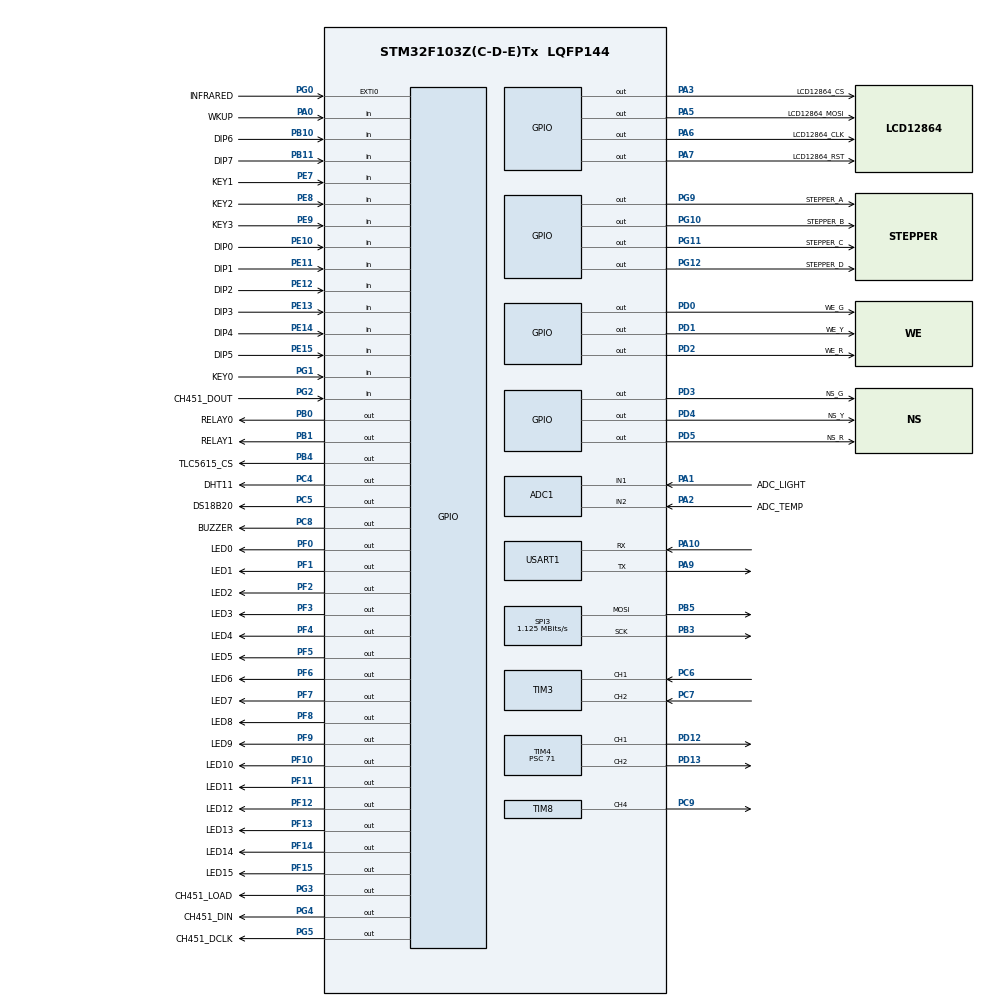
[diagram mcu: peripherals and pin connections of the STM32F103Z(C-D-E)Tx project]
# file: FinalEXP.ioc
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ADC1.Channel-0\#ChannelRegularConversion=ADC_CHANNEL_1
ADC1.Channel-1\#ChannelRegularConversion=ADC_CHANNEL_2
ADC1.ContinuousConvMode=ENABLE
ADC1.NbrOfConversion=2
ADC1.NbrOfConversionFlag=1
ADC1.Rank-0\#ChannelRegularConversion=1
ADC1.Rank-1\#ChannelRegularConversion=2
ADC1.SamplingTime-0\#ChannelRegularConversion=ADC_SAMPLETIME_71CYCLES_5
ADC1.SamplingTime-1\#ChannelRegularConversion=ADC_SAMPLETIME_71CYCLES_5
ADC1.master=1
Dma.ADC1.0.Direction=DMA_PERIPH_TO_MEMORY
Dma.ADC1.0.Instance=DMA1_Channel1
Dma.ADC1.0.MemDataAlignment=DMA_MDATAALIGN_HALFWORD
Dma.ADC1.0.MemInc=DMA_MINC_ENABLE
Dma.ADC1.0.Mode=DMA_CIRCULAR
Dma.ADC1.0.PeriphDataAlignment=DMA_PDATAALIGN_HALFWORD
Dma.ADC1.0.PeriphInc=DMA_PINC_DISABLE
Dma.ADC1.0.Priority=DMA_PRIORITY_LOW
Dma.Request0=ADC1
Dma.Request1=SPI3_TX
Dma.Request2=USART1_RX
Dma.Request3=USART1_TX
Dma.SPI3_TX.1.Direction=DMA_MEMORY_TO_PERIPH
Dma.SPI3_TX.1.Instance=DMA2_Channel2
Dma.SPI3_TX.1.MemDataAlignment=DMA_MDATAALIGN_HALFWORD
Dma.SPI3_TX.1.MemInc=DMA_MINC_ENABLE
Dma.SPI3_TX.1.Mode=DMA_NORMAL
Dma.SPI3_TX.1.PeriphDataAlignment=DMA_PDATAALIGN_HALFWORD
Dma.SPI3_TX.1.PeriphInc=DMA_PINC_DISABLE
Dma.SPI3_TX.1.Priority=DMA_PRIORITY_LOW
Dma.USART1_RX.2.Direction=DMA_PERIPH_TO_MEMORY
Dma.USART1_RX.2.Instance=DMA1_Channel5
Dma.USART1_RX.2.MemDataAlignment=DMA_MDATAALIGN_BYTE
Dma.USART1_RX.2.MemInc=DMA_MINC_ENABLE
Dma.USART1_RX.2.Mode=DMA_NORMAL
Dma.USART1_RX.2.PeriphDataAlignment=DMA_PDATAALIGN_BYTE
Dma.USART1_RX.2.PeriphInc=DMA_PINC_DISABLE
Dma.USART1_RX.2.Priority=DMA_PRIORITY_LOW
Dma.USART1_TX.3.Direction=DMA_MEMORY_TO_PERIPH
Dma.USART1_TX.3.Instance=DMA1_Channel4
Dma.USART1_TX.3.MemDataAlignment=DMA_MDATAALIGN_BYTE
Dma.USART1_TX.3.MemInc=DMA_MINC_ENABLE
Dma.USART1_TX.3.Mode=DMA_NORMAL
Dma.USART1_TX.3.PeriphDataAlignment=DMA_PDATAALIGN_BYTE
Dma.USART1_TX.3.PeriphInc=DMA_PINC_DISABLE
Dma.USART1_TX.3.Priority=DMA_PRIORITY_LOW
FREERTOS.Queues01=DIP2LCDQueue,2,uint8_t,0,Dynamic,NULL,NULL;UARTTXQueue,8,UartMsg_t,0,Dynamic,NULL,NULL
FREERTOS.Tasks01=BtnTask,24,256,StartBtnTask,Default,NULL,Dynamic,NULL,NULL;SwitchTask,16,256,StartSwitchTask,Default,NULL,Dynamic,NULL,NULL;ADCTask,24,256,StartADCTask,Default,NULL,Dynamic,NULL,NULL;UARTTask,32,384,StartUARTTask,Default,NULL,Dynamic,NULL,NULL;TrafficTask,24,256,StartTrafficTask,Default,NULL,Dynamic,NULL,NULL;DisplayTask,24,512,StartDisplayTask,Default,NULL,Dynamic,NULL,NULL;SensorTask,40,256,StartSensorTask,Default,NULL,Dynamic,NULL,NULL;MotorTask,24,256,StartMotorTask,Default,NULL,Dynamic,NULL,NULL;InfraredTask,24,256,StartInfraredTask,Default,NULL,Dynamic,NULL,NULL;DACTask,16,128,StartDACTask,Default,NULL,Dynamic,NULL,NULL;CH451Task,24,256,StartCH451Task,Default,NULL,Dynamic,NULL,NULL
FREERTOS.configTOTAL_HEAP_SIZE=16900
Mcu.Family=STM32F1
Mcu.Name=STM32F103Z(C-D-E)Tx
Mcu.Package=LQFP144
NVIC.DMA1_Channel1_IRQn=true\:5\:0\:false\:false\:true\:true\:false\:true\:true
NVIC.DMA1_Channel4_IRQn=true\:5\:0\:false\:false\:true\:true\:false\:true\:true
NVIC.DMA1_Channel5_IRQn=true\:5\:0\:false\:false\:true\:true\:false\:true\:true
NVIC.DMA2_Channel2_IRQn=true\:5\:0\:false\:false\:true\:true\:false\:true\:true
NVIC.EXTI0_IRQn=true\:5\:0\:false\:false\:true\:true\:true\:true\:true
NVIC.PriorityGroup=NVIC_PRIORITYGROUP_4
NVIC.TIM5_IRQn=true\:5\:0\:false\:false\:true\:true\:true\:true\:true
NVIC.TIM6_IRQn=true\:15\:0\:false\:false\:true\:false\:false\:true\:true
NVIC.TimeBase=TIM6_IRQn
NVIC.TimeBaseIP=TIM6
NVIC.USART1_IRQn=true\:5\:0\:false\:false\:true\:true\:true\:true\:true
OSC_IN.Mode=HSE-External-Oscillator
OSC_IN.Signal=RCC_OSC_IN
OSC_OUT.Mode=HSE-External-Oscillator
OSC_OUT.Signal=RCC_OSC_OUT
PA0-WKUP.GPIO_Label=WKUP
PA0-WKUP.Signal=GPIO_Input
PA1.GPIO_Label=ADC_LIGHT
PA1.Signal=ADCx_IN1
PA10.Mode=Asynchronous
PA10.Signal=USART1_RX
PA13.Mode=Serial_Wire
PA13.Signal=SYS_JTMS-SWDIO
PA14.Mode=Serial_Wire
PA14.Signal=SYS_JTCK-SWCLK
PA2.GPIO_Label=ADC_TEMP
PA2.Signal=ADCx_IN2
PA3.GPIO_Label=LCD12864_CS
PA3.GPIO_Speed=GPIO_SPEED_FREQ_HIGH
PA3.PinState=GPIO_PIN_SET
PA3.Signal=GPIO_Output
PA5.GPIO_Label=LCD12864_MOSI
PA5.GPIO_Speed=GPIO_SPEED_FREQ_HIGH
PA5.Signal=GPIO_Output
PA6.GPIO_Label=LCD12864_CLK
PA6.GPIO_Speed=GPIO_SPEED_FREQ_HIGH
PA6.Signal=GPIO_Output
PA7.GPIO_Label=LCD12864_RST
PA7.GPIO_Speed=GPIO_SPEED_FREQ_HIGH
PA7.Signal=GPIO_Output
PA9.Mode=Asynchronous
PA9.Signal=USART1_TX
PB0.GPIO_Label=RELAY0
PB0.Signal=GPIO_Output
PB1.GPIO_Label=RELAY1
PB1.Signal=GPIO_Output
PB10.GPIO_Label=DIP6
PB10.Signal=GPIO_Input
PB11.GPIO_Label=DIP7
PB11.Signal=GPIO_Input
PB3.Mode=TX_Only_Simplex_Unidirect_Master
PB3.Signal=SPI3_SCK
PB4.GPIO_Label=TLC5615_CS
PB4.Signal=GPIO_Output
PB5.Mode=TX_Only_Simplex_Unidirect_Master
PB5.Signal=SPI3_MOSI
PC4.GPIO_Label=DHT11
PC4.GPIO_ModeDefaultOutputPP=GPIO_MODE_OUTPUT_OD
PC4.GPIO_PuPd=GPIO_NOPULL
PC4.GPIO_Speed=GPIO_SPEED_FREQ_HIGH
PC4.PinState=GPIO_PIN_SET
PC4.Signal=GPIO_Output
PC5.GPIO_Label=DS18B20
PC5.GPIO_ModeDefaultOutputPP=GPIO_MODE_OUTPUT_OD
PC5.GPIO_PuPd=GPIO_NOPULL
PC5.GPIO_Speed=GPIO_SPEED_FREQ_HIGH
PC5.PinState=GPIO_PIN_SET
PC5.Signal=GPIO_Output
PC6.Signal=S_TIM3_CH1
PC7.Signal=S_TIM3_CH2
PC8.GPIO_Label=BUZZER
PC8.GPIO_Speed=GPIO_SPEED_FREQ_MEDIUM
PC8.Signal=GPIO_Output
PC9.Signal=S_TIM8_CH4
PD0.GPIO_Label=WE_G
PD0.GPIO_ModeDefaultOutputPP=GPIO_MODE_OUTPUT_OD
PD0.GPIO_PuPd=GPIO_NOPULL
PD0.GPIO_Speed=GPIO_SPEED_FREQ_LOW
PD0.PinState=GPIO_PIN_SET
PD0.Signal=GPIO_Output
PD1.GPIO_Label=WE_Y
PD1.GPIO_ModeDefaultOutputPP=GPIO_MODE_OUTPUT_OD
PD1.GPIO_PuPd=GPIO_NOPULL
PD1.GPIO_Speed=GPIO_SPEED_FREQ_LOW
PD1.PinState=GPIO_PIN_SET
PD1.Signal=GPIO_Output
PD12.Signal=S_TIM4_CH1
PD13.Signal=S_TIM4_CH2
PD2.GPIO_Label=WE_R
PD2.GPIO_ModeDefaultOutputPP=GPIO_MODE_OUTPUT_OD
PD2.GPIO_PuPd=GPIO_NOPULL
PD2.GPIO_Speed=GPIO_SPEED_FREQ_LOW
PD2.PinState=GPIO_PIN_SET
PD2.Signal=GPIO_Output
PD3.GPIO_Label=NS_G
PD3.GPIO_ModeDefaultOutputPP=GPIO_MODE_OUTPUT_OD
PD3.GPIO_PuPd=GPIO_NOPULL
PD3.GPIO_Speed=GPIO_SPEED_FREQ_LOW
PD3.PinState=GPIO_PIN_SET
PD3.Signal=GPIO_Output
PD4.GPIO_Label=NS_Y
PD4.GPIO_ModeDefaultOutputPP=GPIO_MODE_OUTPUT_OD
PD4.GPIO_PuPd=GPIO_NOPULL
PD4.GPIO_Speed=GPIO_SPEED_FREQ_LOW
PD4.PinState=GPIO_PIN_SET
PD4.Signal=GPIO_Output
PD5.GPIO_Label=NS_R
PD5.GPIO_ModeDefaultOutputPP=GPIO_MODE_OUTPUT_OD
PD5.GPIO_PuPd=GPIO_NOPULL
PD5.GPIO_Speed=GPIO_SPEED_FREQ_LOW
PD5.PinState=GPIO_PIN_SET
PD5.Signal=GPIO_Output
PE10.GPIO_Label=DIP0
PE10.Signal=GPIO_Input
PE11.GPIO_Label=DIP1
PE11.Signal=GPIO_Input
PE12.GPIO_Label=DIP2
PE12.Signal=GPIO_Input
PE13.GPIO_Label=DIP3
PE13.Signal=GPIO_Input
PE14.GPIO_Label=DIP4
PE14.Signal=GPIO_Input
PE15.GPIO_Label=DIP5
PE15.Signal=GPIO_Input
PE7.GPIO_Label=KEY1
PE7.Signal=GPIO_Input
PE8.GPIO_Label=KEY2
PE8.Signal=GPIO_Input
PE9.GPIO_Label=KEY3
PE9.Signal=GPIO_Input
PF0.GPIO_Label=LED0
PF0.Signal=GPIO_Output
PF1.GPIO_Label=LED1
PF1.GPIO_ModeDefaultOutputPP=GPIO_MODE_OUTPUT_OD
PF1.GPIO_PuPd=GPIO_NOPULL
PF1.PinState=GPIO_PIN_SET
PF1.Signal=GPIO_Output
PF10.GPIO_Label=LED10
PF10.GPIO_ModeDefaultOutputPP=GPIO_MODE_OUTPUT_OD
PF10.GPIO_PuPd=GPIO_NOPULL
PF10.PinState=GPIO_PIN_SET
PF10.Signal=GPIO_Output
PF11.GPIO_Label=LED11
PF11.GPIO_ModeDefaultOutputPP=GPIO_MODE_OUTPUT_OD
PF11.GPIO_PuPd=GPIO_NOPULL
PF11.PinState=GPIO_PIN_SET
PF11.Signal=GPIO_Output
PF12.GPIO_Label=LED12
PF12.GPIO_ModeDefaultOutputPP=GPIO_MODE_OUTPUT_OD
PF12.GPIO_PuPd=GPIO_NOPULL
PF12.PinState=GPIO_PIN_SET
PF12.Signal=GPIO_Output
PF13.GPIO_Label=LED13
PF13.GPIO_ModeDefaultOutputPP=GPIO_MODE_OUTPUT_OD
PF13.GPIO_PuPd=GPIO_NOPULL
PF13.PinState=GPIO_PIN_SET
PF13.Signal=GPIO_Output
PF14.GPIO_Label=LED14
PF14.GPIO_ModeDefaultOutputPP=GPIO_MODE_OUTPUT_OD
PF14.GPIO_PuPd=GPIO_NOPULL
PF14.PinState=GPIO_PIN_SET
PF14.Signal=GPIO_Output
PF15.GPIO_Label=LED15
PF15.GPIO_ModeDefaultOutputPP=GPIO_MODE_OUTPUT_OD
PF15.GPIO_PuPd=GPIO_NOPULL
PF15.PinState=GPIO_PIN_SET
PF15.Signal=GPIO_Output
PF2.GPIO_Label=LED2
PF2.GPIO_ModeDefaultOutputPP=GPIO_MODE_OUTPUT_OD
PF2.GPIO_PuPd=GPIO_NOPULL
PF2.PinState=GPIO_PIN_SET
PF2.Signal=GPIO_Output
PF3.GPIO_Label=LED3
PF3.GPIO_ModeDefaultOutputPP=GPIO_MODE_OUTPUT_OD
PF3.GPIO_PuPd=GPIO_NOPULL
PF3.PinState=GPIO_PIN_SET
PF3.Signal=GPIO_Output
PF4.GPIO_Label=LED4
PF4.GPIO_ModeDefaultOutputPP=GPIO_MODE_OUTPUT_OD
PF4.GPIO_PuPd=GPIO_NOPULL
PF4.PinState=GPIO_PIN_SET
PF4.Signal=GPIO_Output
PF5.GPIO_Label=LED5
PF5.GPIO_ModeDefaultOutputPP=GPIO_MODE_OUTPUT_OD
PF5.GPIO_PuPd=GPIO_NOPULL
PF5.PinState=GPIO_PIN_SET
PF5.Signal=GPIO_Output
PF6.GPIO_Label=LED6
PF6.GPIO_ModeDefaultOutputPP=GPIO_MODE_OUTPUT_OD
PF6.GPIO_PuPd=GPIO_NOPULL
PF6.PinState=GPIO_PIN_SET
PF6.Signal=GPIO_Output
PF7.GPIO_Label=LED7
PF7.GPIO_ModeDefaultOutputPP=GPIO_MODE_OUTPUT_OD
PF7.GPIO_PuPd=GPIO_NOPULL
PF7.PinState=GPIO_PIN_SET
PF7.Signal=GPIO_Output
PF8.GPIO_Label=LED8
PF8.GPIO_ModeDefaultOutputPP=GPIO_MODE_OUTPUT_OD
PF8.GPIO_PuPd=GPIO_NOPULL
PF8.PinState=GPIO_PIN_SET
PF8.Signal=GPIO_Output
PF9.GPIO_Label=LED9
PF9.GPIO_ModeDefaultOutputPP=GPIO_MODE_OUTPUT_OD
PF9.GPIO_PuPd=GPIO_NOPULL
PF9.PinState=GPIO_PIN_SET
PF9.Signal=GPIO_Output
PG0.GPIO_Label=INFRARED
PG0.GPIO_ModeDefaultEXTI=GPIO_MODE_IT_RISING_FALLING
PG0.Signal=GPXTI0
PG1.GPIO_Label=KEY0
PG1.Signal=GPIO_Input
PG10.GPIO_Label=STEPPER_B
PG10.PinState=GPIO_PIN_SET
PG10.Signal=GPIO_Output
PG11.GPIO_Label=STEPPER_C
PG11.PinState=GPIO_PIN_SET
PG11.Signal=GPIO_Output
PG12.GPIO_Label=STEPPER_D
PG12.PinState=GPIO_PIN_SET
PG12.Signal=GPIO_Output
PG2.GPIO_Label=CH451_DOUT
PG2.Signal=GPIO_Input
PG3.GPIO_Label=CH451_LOAD
PG3.GPIO_ModeDefaultOutputPP=GPIO_MODE_OUTPUT_PP
PG3.GPIO_Speed=GPIO_SPEED_FREQ_HIGH
PG3.PinState=GPIO_PIN_SET
PG3.Signal=GPIO_Output
PG4.GPIO_Label=CH451_DIN
PG4.GPIO_ModeDefaultOutputPP=GPIO_MODE_OUTPUT_PP
PG4.GPIO_Speed=GPIO_SPEED_FREQ_HIGH
PG4.PinState=GPIO_PIN_SET
PG4.Signal=GPIO_Output
PG5.GPIO_Label=CH451_DCLK
PG5.GPIO_ModeDefaultOutputPP=GPIO_MODE_OUTPUT_PP
PG5.GPIO_Speed=GPIO_SPEED_FREQ_HIGH
PG5.PinState=GPIO_PIN_SET
PG5.Signal=GPIO_Output
PG9.GPIO_Label=STEPPER_A
PG9.PinState=GPIO_PIN_SET
PG9.Signal=GPIO_Output
ProjectManager.HeapSize=0x200
ProjectManager.StackSize=0x400
ProjectManager.TargetToolchain=CMake
RCC.ADCPresc=RCC_ADCPCLK2_DIV6
RCC.AHBFreq_Value=72000000
RCC.APB1CLKDivider=RCC_HCLK_DIV2
RCC.APB1Freq_Value=36000000
RCC.APB1TimFreq_Value=72000000
RCC.APB2Freq_Value=72000000
RCC.APB2TimFreq_Value=72000000
RCC.HCLKFreq_Value=72000000
RCC.PLLMUL=RCC_PLL_MUL9
RCC.PLLSourceVirtual=RCC_PLLSOURCE_HSE
RCC.SYSCLKFreq_VALUE=72000000
RCC.SYSCLKSource=RCC_SYSCLKSOURCE_PLLCLK
RCC.USBFreq_Value=72000000
SH.ADCx_IN1.0=ADC1_IN1,IN1
SH.ADCx_IN2.0=ADC1_IN2,IN2
SH.S_TIM3_CH1.0=TIM3_CH1,Encoder_Interface
SH.S_TIM3_CH2.0=TIM3_CH2,Encoder_Interface
SH.S_TIM4_CH1.0=TIM4_CH1,PWM Generation1 CH1
SH.S_TIM4_CH2.0=TIM4_CH2,PWM Generation2 CH2
SH.S_TIM8_CH4.0=TIM8_CH4,PWM Generation4 CH4
SPI3.BaudRatePrescaler=SPI_BAUDRATEPRESCALER_32
SPI3.CalculateBaudRate=1.125 MBits/s
SPI3.DataSize=SPI_DATASIZE_16BIT
SPI3.Direction=SPI_DIRECTION_2LINES
SPI3.Mode=SPI_MODE_MASTER
SPI3.VirtualType=VM_MASTER
TIM3.AutoReloadPreload=TIM_AUTORELOAD_PRELOAD_ENABLE
TIM3.EncoderMode=TIM_ENCODERMODE_TI12
TIM3.IC2Polarity=TIM_ICPOLARITY_FALLING
TIM4.AutoReloadPreload=TIM_AUTORELOAD_PRELOAD_ENABLE
TIM4.Channel-PWM\ Generation1\ CH1=TIM_CHANNEL_1
TIM4.Channel-PWM\ Generation2\ CH2=TIM_CHANNEL_2
TIM4.Period=999
TIM4.Prescaler=71
TIM5.AutoReloadPreload=TIM_AUTORELOAD_PRELOAD_ENABLE
TIM5.Period=29999
TIM5.Prescaler=7199
TIM7.AutoReloadPreload=TIM_AUTORELOAD_PRELOAD_ENABLE
TIM7.Prescaler=71
TIM8.AutoReloadPreload=TIM_AUTORELOAD_PRELOAD_ENABLE
TIM8.Channel-PWM\ Generation4\ CH4=TIM_CHANNEL_4
TIM8.Period=1999
TIM8.Prescaler=719
USART1.VirtualMode=VM_ASYNC
VP_FREERTOS_VS_CMSIS_V2.Mode=CMSIS_V2
VP_SYS_VS_tim6.Mode=TIM6
VP_TIM4_VS_ClockSourceINT.Mode=Internal
VP_TIM5_VS_ClockSourceINT.Mode=Internal
VP_TIM7_VS_ClockSourceINT.Mode=Enable_Timer
VP_TIM8_VS_ClockSourceINT.Mode=Internal
board=custom

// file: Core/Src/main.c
/* USER CODE BEGIN Header */
/**
 ******************************************************************************
 * @file           : main.c
 * @brief          : Main program body
 ******************************************************************************
 * @attention
 *
 * Copyright (c) 2026 STMicroelectronics.
 * All rights reserved.
 *
 * This software is licensed under terms that can be found in the LICENSE file
 * in the root directory of this software component.
 * If no LICENSE file comes with this software, it is provided AS-IS.
 *
 ******************************************************************************
 */
/* USER CODE END Header */
#include "main.h"
#include "adc.h"
#include "cmsis_os.h"
#include "dma.h"
#include "gpio.h"
#include "spi.h"
#include "tim.h"
#include "usart.h"

/* USER CODE BEGIN Includes */
#include "DelayUs.h"
#include "KeyScan.h"
#include "LCD12864.h"
#include "btn.h"
#include "dc_motor.h"
#include "ir_receiver.h"
#include <string.h>

/* USER CODE END Includes */

/* USER CODE BEGIN PV */
volatile uint16_t
  adc_value[2]; // 存放 ADC 值，adc_value[0] 存放光敏电阻的采样值，adc_value[1] 存放热敏电阻的采样值
uint8_t rxData[50]; // 接收缓冲区（用于回显）

/* USER CODE END PV */

void SystemClock_Config(void);
void MX_FREERTOS_Init(void);
/* USER CODE BEGIN PFP */
extern osMessageQueueId_t UARTTXQueueHandle;

/* USER CODE END PFP */

/* USER CODE BEGIN 0 */
LED_DisplayMode_t LED_displayMode = LED_DISPLAY_LIGHT;          // 默认显示光敏电阻的采样值
TrafficLightState_t trafficLightState = NS_GREEN_WE_RED;        // 初始化交通灯状态为南北绿，东西红
volatile DeviceControlMode_t deviceControlMode = RELAY_CONTROL; // 初始化设备控制模式为继电器控制
volatile MotorStartStopState_t motorStartStopState = MOTOR_OFF; // 初始化电机开关状态为关闭
volatile MotorMode_t motorMode = MOTOR_MODE1;                   // 初始化电机预设模式
/* USER CODE END 0 */

int
main(void)
{

    /* MCU Configuration--------------------------------------------------------*/

    /* Reset of all peripherals, Initializes the Flash interface and the Systick. */

    HAL_Init();

    /* Configure the system clock */
    SystemClock_Config();

    /* Initialize all configured peripherals */
    MX_GPIO_Init();
    MX_DMA_Init();
    MX_ADC1_Init();
    MX_USART1_UART_Init();
    MX_TIM5_Init();
    MX_SPI3_Init();
    MX_TIM8_Init();
    MX_TIM4_Init();
    MX_TIM7_Init();
    MX_TIM3_Init();
    /* USER CODE BEGIN 2 */
    // 初始化按键
    Btn_Init();
    KeyScan_Init();

    Delay_Init();

    // 初始化 LCD12864
    LCD_Init();
    LCD_Clear();
    IR_Receiver_Init(); // 初始化红外接收器

    // 启动 ADC DMA 采集，连续采集光敏电阻和热敏电阻的模拟值，并存放到 adc_value 数组中
    HAL_ADC_Start_DMA(&hadc1, (uint32_t *)adc_value, 2);

    // 启动 TIM5 中断，用于每 3 秒切换一次交通灯状态
    HAL_TIM_Base_Start_IT(&htim5);

    // 启动 UART 接收，使用空闲中断模式，接收数据存放到 rxData 数组中
    HAL_UARTEx_ReceiveToIdle_DMA(&huart1, rxData, sizeof(rxData));

    // 关闭 DMA 传输过半中断
    __HAL_DMA_DISABLE_IT(&hdma_usart1_rx, DMA_IT_HT);
    /* USER CODE END 2 */

    /* Init scheduler */
    osKernelInitialize(); /* Call init function for freertos objects (in cmsis_os2.c) */
    MX_FREERTOS_Init();

    /* Start scheduler */
    osKernelStart();

    /* We should never get here as control is now taken by the scheduler */

    /* Infinite loop */
    while(1)
    {

    }
}

void
SystemClock_Config(void)
{
    RCC_OscInitTypeDef RCC_OscInitStruct = { 0 };
    RCC_ClkInitTypeDef RCC_ClkInitStruct = { 0 };
    RCC_PeriphCLKInitTypeDef PeriphClkInit = { 0 };

    /** Initializes the RCC Oscillators according to the specified parameters
     * in the RCC_OscInitTypeDef structure.
     */
    RCC_OscInitStruct.OscillatorType = RCC_OSCILLATORTYPE_HSE;
    RCC_OscInitStruct.HSEState = RCC_HSE_ON;
    RCC_OscInitStruct.HSEPredivValue = RCC_HSE_PREDIV_DIV1;
    RCC_OscInitStruct.HSIState = RCC_HSI_ON;
    RCC_OscInitStruct.PLL.PLLState = RCC_PLL_ON;
    RCC_OscInitStruct.PLL.PLLSource = RCC_PLLSOURCE_HSE;
    RCC_OscInitStruct.PLL.PLLMUL = RCC_PLL_MUL9;
    if(HAL_RCC_OscConfig(&RCC_OscInitStruct) != HAL_OK)
    {
        Error_Handler();
    }

    /** Initializes the CPU, AHB and APB buses clocks
     */
    RCC_ClkInitStruct.ClockType =
      RCC_CLOCKTYPE_HCLK | RCC_CLOCKTYPE_SYSCLK | RCC_CLOCKTYPE_PCLK1 | RCC_CLOCKTYPE_PCLK2;
    RCC_ClkInitStruct.SYSCLKSource = RCC_SYSCLKSOURCE_PLLCLK;
    RCC_ClkInitStruct.AHBCLKDivider = RCC_SYSCLK_DIV1;
    RCC_ClkInitStruct.APB1CLKDivider = RCC_HCLK_DIV2;
    RCC_ClkInitStruct.APB2CLKDivider = RCC_HCLK_DIV1;

    if(HAL_RCC_ClockConfig(&RCC_ClkInitStruct, FLASH_LATENCY_2) != HAL_OK)
    {
        Error_Handler();
    }
    PeriphClkInit.PeriphClockSelection = RCC_PERIPHCLK_ADC;
    PeriphClkInit.AdcClockSelection = RCC_ADCPCLK2_DIV6;
    if(HAL_RCCEx_PeriphCLKConfig(&PeriphClkInit) != HAL_OK)
    {
        Error_Handler();
    }
}

/* USER CODE BEGIN 4 */
void
HAL_UARTEx_RxEventCallback(UART_HandleTypeDef *huart, uint16_t Size)
{
    if(huart->Instance == USART1)
    {
        // 回显接收到的数据（通过 UART 发送队列）
        if(UARTTXQueueHandle != NULL)
        {
            UartMsg_t msg;
            uint16_t copy_len = Size;

            if(copy_len > UART_TX_MAX_LEN)
            {
                copy_len = UART_TX_MAX_LEN;
            }

            msg.len = copy_len;
            memcpy(msg.data, rxData, copy_len);
            (void)osMessageQueuePut(UARTTXQueueHandle, &msg, 0, 0);
        }
        // 重新启动 UART 接收
        HAL_UARTEx_ReceiveToIdle_DMA(&huart1, rxData, sizeof(rxData));
    }
}
/* USER CODE END 4 */

void
HAL_TIM_PeriodElapsedCallback(TIM_HandleTypeDef *htim)
{
    /* USER CODE BEGIN Callback 0 */
    if(htim->Instance == TIM5)
    {
        // 每 3 秒切换一次交通灯状态
        switch(trafficLightState)
        {
            case NS_GREEN_WE_RED:
                trafficLightState = NS_YELLOW_WE_RED;
                break;

            case NS_YELLOW_WE_RED:
                trafficLightState = NS_RED_WE_GREEN;
                break;

            case NS_RED_WE_GREEN:
                trafficLightState = NS_RED_WE_YELLOW;
                break;

            case NS_RED_WE_YELLOW:
                trafficLightState = NS_GREEN_WE_RED;
                break;
        }
    }
    /* USER CODE END Callback 0 */
    if(htim->Instance == TIM6)
    {
        HAL_IncTick();
    }
}

void
Error_Handler(void)
{
    __disable_irq();
    while(1)
    {
    }
}

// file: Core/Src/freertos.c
/* USER CODE BEGIN Header */
/**
 ******************************************************************************
 * File Name          : freertos.c
 * Description        : Code for freertos applications
 ******************************************************************************
 * @attention
 *
 * Copyright (c) 2026 STMicroelectronics.
 * All rights reserved.
 *
 * This software is licensed under terms that can be found in the LICENSE file
 * in the root directory of this software component.
 * If no LICENSE file comes with this software, it is provided AS-IS.
 *
 ******************************************************************************
 */
/* USER CODE END Header */

#include "FreeRTOS.h"
#include "cmsis_os.h"
#include "main.h"
#include "task.h"

/* USER CODE BEGIN Includes */
#include "KeyScan.h"
#include "LCD12864.h"
#include "btn.h"
#include "ch451.h"
#include "dc_motor.h"
#include "dht11.h"
#include "ds18b20.h"
#include "ir_receiver.h"
#include "led.h"
#include "servo_motor.h"
#include "spi.h"
#include "stepper_motor.h"
#include "usart.h"
#include <stdio.h>
#include <string.h>

/* USER CODE END Includes */

/* USER CODE BEGIN PD */
#define BTN_DEBOUNCE_DELAY 40 // 按键消抖时间，单位 ms
/* USER CODE END PD */

/* Definitions for BtnTask */
osThreadId_t BtnTaskHandle;
const osThreadAttr_t BtnTask_attributes = {
    .name = "BtnTask",
    .stack_size = 256 * 4,
    .priority = (osPriority_t)osPriorityNormal,
};
/* Definitions for SwitchTask */
osThreadId_t SwitchTaskHandle;
const osThreadAttr_t SwitchTask_attributes = {
    .name = "SwitchTask",
    .stack_size = 256 * 4,
    .priority = (osPriority_t)osPriorityBelowNormal,
};
/* Definitions for ADCTask */
osThreadId_t ADCTaskHandle;
const osThreadAttr_t ADCTask_attributes = {
    .name = "ADCTask",
    .stack_size = 256 * 4,
    .priority = (osPriority_t)osPriorityNormal,
};
/* Definitions for UARTTask */
osThreadId_t UARTTaskHandle;
const osThreadAttr_t UARTTask_attributes = {
    .name = "UARTTask",
    .stack_size = 384 * 4,
    .priority = (osPriority_t)osPriorityAboveNormal,
};
/* Definitions for TrafficTask */
osThreadId_t TrafficTaskHandle;
const osThreadAttr_t TrafficTask_attributes = {
    .name = "TrafficTask",
    .stack_size = 256 * 4,
    .priority = (osPriority_t)osPriorityNormal,
};
/* Definitions for DisplayTask */
osThreadId_t DisplayTaskHandle;
const osThreadAttr_t DisplayTask_attributes = {
    .name = "DisplayTask",
    .stack_size = 512 * 4,
    .priority = (osPriority_t)osPriorityNormal,
};
/* Definitions for SensorTask */
osThreadId_t SensorTaskHandle;
const osThreadAttr_t SensorTask_attributes = {
    .name = "SensorTask",
    .stack_size = 256 * 4,
    .priority = (osPriority_t)osPriorityHigh,
};
/* Definitions for MotorTask */
osThreadId_t MotorTaskHandle;
const osThreadAttr_t MotorTask_attributes = {
    .name = "MotorTask",
    .stack_size = 256 * 4,
    .priority = (osPriority_t)osPriorityNormal,
};
/* Definitions for InfraredTask */
osThreadId_t InfraredTaskHandle;
const osThreadAttr_t InfraredTask_attributes = {
    .name = "InfraredTask",
    .stack_size = 256 * 4,
    .priority = (osPriority_t)osPriorityNormal,
};
/* Definitions for DACTask */
osThreadId_t DACTaskHandle;
const osThreadAttr_t DACTask_attributes = {
    .name = "DACTask",
    .stack_size = 128 * 4,
    .priority = (osPriority_t)osPriorityBelowNormal,
};
/* Definitions for CH451Task */
osThreadId_t CH451TaskHandle;
const osThreadAttr_t CH451Task_attributes = {
    .name = "CH451Task",
    .stack_size = 256 * 4,
    .priority = (osPriority_t)osPriorityNormal,
};
/* Definitions for DIP2LCDQueue */
osMessageQueueId_t DIP2LCDQueueHandle;
const osMessageQueueAttr_t DIP2LCDQueue_attributes = { .name = "DIP2LCDQueue" };
/* Definitions for UARTTXQueue */
osMessageQueueId_t UARTTXQueueHandle;
const osMessageQueueAttr_t UARTTXQueue_attributes = { .name = "UARTTXQueue" };

void StartBtnTask(void *argument);
void StartSwitchTask(void *argument);
void StartADCTask(void *argument);
void StartUARTTask(void *argument);
void StartTrafficTask(void *argument);
void StartDisplayTask(void *argument);
void StartSensorTask(void *argument);
void StartMotorTask(void *argument);
void StartInfraredTask(void *argument);
void StartDACTask(void *argument);
void StartCH451Task(void *argument);

void MX_FREERTOS_Init(void); /* (MISRA C 2004 rule 8.1) */

void
MX_FREERTOS_Init(void)
{

    /* Create the queue(s) */
    /* creation of DIP2LCDQueue */
    DIP2LCDQueueHandle = osMessageQueueNew(2, sizeof(uint8_t), &DIP2LCDQueue_attributes);

    /* creation of UARTTXQueue */
    UARTTXQueueHandle = osMessageQueueNew(8, sizeof(UartMsg_t), &UARTTXQueue_attributes);

    /* Create the thread(s) */
    /* creation of BtnTask */
    BtnTaskHandle = osThreadNew(StartBtnTask, NULL, &BtnTask_attributes);

    /* creation of SwitchTask */
    SwitchTaskHandle = osThreadNew(StartSwitchTask, NULL, &SwitchTask_attributes);

    /* creation of ADCTask */
    ADCTaskHandle = osThreadNew(StartADCTask, NULL, &ADCTask_attributes);

    /* creation of UARTTask */
    UARTTaskHandle = osThreadNew(StartUARTTask, NULL, &UARTTask_attributes);

    /* creation of TrafficTask */
    TrafficTaskHandle = osThreadNew(StartTrafficTask, NULL, &TrafficTask_attributes);

    /* creation of DisplayTask */
    DisplayTaskHandle = osThreadNew(StartDisplayTask, NULL, &DisplayTask_attributes);

    /* creation of SensorTask */
    SensorTaskHandle = osThreadNew(StartSensorTask, NULL, &SensorTask_attributes);

    /* creation of MotorTask */
    MotorTaskHandle = osThreadNew(StartMotorTask, NULL, &MotorTask_attributes);

    /* creation of InfraredTask */
    InfraredTaskHandle = osThreadNew(StartInfraredTask, NULL, &InfraredTask_attributes);

    /* creation of DACTask */
    DACTaskHandle = osThreadNew(StartDACTask, NULL, &DACTask_attributes);

    /* creation of CH451Task */
    CH451TaskHandle = osThreadNew(StartCH451Task, NULL, &CH451Task_attributes);

}

void
StartBtnTask(void *argument)
{
    /* USER CODE BEGIN StartBtnTask */
    uint8_t debounceCounter; // 消抖计数器
    /* Infinite loop */
    for(;;)
    {
        // 读取按键状态
        uint8_t btnPressed = HAL_GPIO_ReadPin(WKUP_GPIO_Port, WKUP_Pin) == GPIO_PIN_RESET;
        switch(btnState)
        {
            case BTN_STATE_IDLE:
                if(btnPressed)
                {
                    btnState = BTN_STATE_DEBOUNCE;
                    debounceCounter = 0;
                }
                break;

            case BTN_STATE_DEBOUNCE:
                if(btnPressed)
                {
                    debounceCounter++;
                    if(debounceCounter >= BTN_DEBOUNCE_DELAY / 20)
                    { // 每 20 ms 检查一次
                        btnState = BTN_STATE_PRESSED;
                    }
                }
                else
                {
                    btnState = BTN_STATE_IDLE; // 按键抖动，回到空闲状态
                }
                break;

            case BTN_STATE_PRESSED:
                if(btnPressed)
                {
                    break;
                }

                btnEvent = BTN_EVENT_CLICK; // 点击事件
                btnState = BTN_STATE_IDLE;  // 回到空闲状态
                break;
        }

        KeyScan_ScanAll(); // 检测四个独立按键的状态

        osDelay(20);
    }
    /* USER CODE END StartBtnTask */
}

void
StartSwitchTask(void *argument)
{
    /* USER CODE BEGIN StartSwitchTask */
    /* Infinite loop */
    for(;;)
    {
        // 读取 DIP 开关状态，发送到 DisplayTask 显示
        uint8_t dipState = 0;
        dipState |= (HAL_GPIO_ReadPin(DIP0_GPIO_Port, DIP0_Pin) == GPIO_PIN_RESET) ? 0x01 : 0x00;
        dipState |= (HAL_GPIO_ReadPin(DIP1_GPIO_Port, DIP1_Pin) == GPIO_PIN_RESET) ? 0x02 : 0x00;
        dipState |= (HAL_GPIO_ReadPin(DIP2_GPIO_Port, DIP2_Pin) == GPIO_PIN_RESET) ? 0x04 : 0x00;
        dipState |= (HAL_GPIO_ReadPin(DIP3_GPIO_Port, DIP3_Pin) == GPIO_PIN_RESET) ? 0x08 : 0x00;
        dipState |= (HAL_GPIO_ReadPin(DIP4_GPIO_Port, DIP4_Pin) == GPIO_PIN_RESET) ? 0x10 : 0x00;
        dipState |= (HAL_GPIO_ReadPin(DIP5_GPIO_Port, DIP5_Pin) == GPIO_PIN_RESET) ? 0x20 : 0x00;
        dipState |= (HAL_GPIO_ReadPin(DIP6_GPIO_Port, DIP6_Pin) == GPIO_PIN_RESET) ? 0x40 : 0x00;
        dipState |= (HAL_GPIO_ReadPin(DIP7_GPIO_Port, DIP7_Pin) == GPIO_PIN_RESET) ? 0x80 : 0x00;
        osMessageQueuePut(DIP2LCDQueueHandle, &dipState, 0, 0);

        // 独立按键 KEY3 控制设备控制模式的切换
        if(keyEvent[3] == KEY_EVENT_CLICK)
        {
            keyEvent[3] = KEY_EVENT_NONE; // 清除事件
            switch(deviceControlMode)
            {
                case RELAY_CONTROL:
                    deviceControlMode = STEPPER_MOTOR_CONTROL;
                    break;

                case STEPPER_MOTOR_CONTROL:
                    deviceControlMode = DC_MOTOR_CONTROL;
                    break;

                case DC_MOTOR_CONTROL:
                    deviceControlMode = SERVO_MOTOR_CONTROL;
                    break;

                case SERVO_MOTOR_CONTROL:
                    deviceControlMode = RELAY_CONTROL;
                    break;
            }

            // 切换设备控制模式时，电机关闭，预设模式重置
            motorStartStopState = MOTOR_OFF;
            motorMode = MOTOR_MODE1;
        }

        // 处于继电器控制模式时，独立按键 KEY0 和 KEY1 控制继电器 RELAY0 和 RELAY1 的开关
        if(deviceControlMode == RELAY_CONTROL)
        {
            // 根据独立按键 KEY0 和 KEY1 的状态，控制继电器 RELAY0 和 RELAY1 的开关
            if(keyEvent[0] == KEY_EVENT_CLICK)
            {
                keyEvent[0] = KEY_EVENT_NONE; // 清除事件
                HAL_GPIO_TogglePin(RELAY0_GPIO_Port, RELAY0_Pin);
            }
            if(keyEvent[1] == KEY_EVENT_CLICK)
            {
                keyEvent[1] = KEY_EVENT_NONE; // 清除事件
                HAL_GPIO_TogglePin(RELAY1_GPIO_Port, RELAY1_Pin);
            }
        }
        else
        {
            // 非继电器控制模式下，继电器断开
            HAL_GPIO_WritePin(RELAY0_GPIO_Port, RELAY0_Pin, GPIO_PIN_RESET);
            HAL_GPIO_WritePin(RELAY1_GPIO_Port, RELAY1_Pin, GPIO_PIN_RESET);
        }
        osDelay(100);
    }
    /* USER CODE END StartSwitchTask */
}

void
StartADCTask(void *argument)
{
    /* USER CODE BEGIN StartADCTask */

    /* Infinite loop */
    for(;;)
    {
        // 根据按键事件切换显示模式
        if(btnEvent == BTN_EVENT_CLICK)
        {
            btnEvent = BTN_EVENT_NONE; // 清除事件
            if(LED_displayMode == LED_DISPLAY_LIGHT)
            {
                LED_displayMode = LED_DISPLAY_TEMP; // 切换到显示热敏电阻
            }
            else
            {
                LED_displayMode = LED_DISPLAY_LIGHT; // 切换到显示光敏电阻
            }
        }

        // 根据当前显示模式，切换 LED 显示光敏电阻的采样值还是热敏电阻的采样值
        if(LED_displayMode == LED_DISPLAY_LIGHT)
        {
            // 通过板载 LED 显示光敏电阻的采样值，adc_value[0]，范围 0~4095，点亮 LED0 到 LED11
            LED_Binary_Display(adc_value[0]);
        }
        else if(LED_displayMode == LED_DISPLAY_TEMP)
        {
            // 通过板载 LED 显示热敏电阻的采样值，adc_value[1]，范围 0~4095，点亮 LED0 到 LED11
            LED_Binary_Display(adc_value[1]);
        }
        osDelay(200);
    }
    /* USER CODE END StartADCTask */
}

void
StartUARTTask(void *argument)
{
    /* USER CODE BEGIN StartUARTTask */
    UartMsg_t msg;
    /* Infinite loop */
    for(;;)
    {
        // 从 UART 接收队列获取数据，并通过 UART 发送出去
        if(osMessageQueueGet(UARTTXQueueHandle, &msg, NULL, osWaitForever) == osOK)
        {
            if(msg.len > 0)
            {
                if(msg.len > UART_TX_MAX_LEN)
                {
                    msg.len = UART_TX_MAX_LEN;
                }

                while(HAL_UART_Transmit_DMA(&huart1, msg.data, msg.len) != HAL_OK)
                {
                    osDelay(10);
                }

                while(huart1.gState != HAL_UART_STATE_READY)
                {
                    osDelay(10);
                }
            }
        }
        osDelay(100);
    }
    /* USER CODE END StartUARTTask */
}

void
StartTrafficTask(void *argument)
{
    /* USER CODE BEGIN StartTrafficTask */
    /* Infinite loop */
    for(;;)
    {
        // 根据 trafficLightState 的状态，控制交通灯的 LED 显示(低电平点亮 LED)
        switch(trafficLightState)
        {
            case NS_GREEN_WE_RED:
                HAL_GPIO_WritePin(NS_G_GPIO_Port, NS_G_Pin, GPIO_PIN_RESET);
                HAL_GPIO_WritePin(NS_Y_GPIO_Port, NS_Y_Pin, GPIO_PIN_SET);
                HAL_GPIO_WritePin(NS_R_GPIO_Port, NS_R_Pin, GPIO_PIN_SET);
                HAL_GPIO_WritePin(WE_G_GPIO_Port, WE_G_Pin, GPIO_PIN_SET);
                HAL_GPIO_WritePin(WE_Y_GPIO_Port, WE_Y_Pin, GPIO_PIN_SET);
                HAL_GPIO_WritePin(WE_R_GPIO_Port, WE_R_Pin, GPIO_PIN_RESET);
                break;

            case NS_YELLOW_WE_RED:
                HAL_GPIO_WritePin(NS_G_GPIO_Port, NS_G_Pin, GPIO_PIN_SET);
                HAL_GPIO_WritePin(NS_Y_GPIO_Port, NS_Y_Pin, GPIO_PIN_RESET);
                HAL_GPIO_WritePin(NS_R_GPIO_Port, NS_R_Pin, GPIO_PIN_SET);
                HAL_GPIO_WritePin(WE_G_GPIO_Port, WE_G_Pin, GPIO_PIN_SET);
                HAL_GPIO_WritePin(WE_Y_GPIO_Port, WE_Y_Pin, GPIO_PIN_SET);
                HAL_GPIO_WritePin(WE_R_GPIO_Port, WE_R_Pin, GPIO_PIN_RESET);
                break;

            case NS_RED_WE_GREEN:
                HAL_GPIO_WritePin(NS_G_GPIO_Port, NS_G_Pin, GPIO_PIN_SET);
                HAL_GPIO_WritePin(NS_Y_GPIO_Port, NS_Y_Pin, GPIO_PIN_SET);
                HAL_GPIO_WritePin(NS_R_GPIO_Port, NS_R_Pin, GPIO_PIN_RESET);
                HAL_GPIO_WritePin(WE_G_GPIO_Port, WE_G_Pin, GPIO_PIN_RESET);
                HAL_GPIO_WritePin(WE_Y_GPIO_Port, WE_Y_Pin, GPIO_PIN_SET);
                HAL_GPIO_WritePin(WE_R_GPIO_Port, WE_R_Pin, GPIO_PIN_SET);
                break;

            case NS_RED_WE_YELLOW:
                HAL_GPIO_WritePin(NS_G_GPIO_Port, NS_G_Pin, GPIO_PIN_SET);
                HAL_GPIO_WritePin(NS_Y_GPIO_Port, NS_Y_Pin, GPIO_PIN_SET);
                HAL_GPIO_WritePin(NS_R_GPIO_Port, NS_R_Pin, GPIO_PIN_RESET);
                HAL_GPIO_WritePin(WE_G_GPIO_Port, WE_G_Pin, GPIO_PIN_SET);
                HAL_GPIO_WritePin(WE_Y_GPIO_Port, WE_Y_Pin, GPIO_PIN_RESET);
                HAL_GPIO_WritePin(WE_R_GPIO_Port, WE_R_Pin, GPIO_PIN_SET);
                break;
        }
        osDelay(1000);
    }
    /* USER CODE END StartTrafficTask */
}

void
StartDisplayTask(void *argument)
{
    /* USER CODE BEGIN StartDisplayTask */
    // 显存
    char row1[17] = { 0 };
    char row2[17] = { 0 };
    char row3[17] = { 0 };
    char row4[17] = { 0 };
    char row1Text[32] = { 0 };
    char row4Text[32] = { 0 };

    const char *trafficText = "NS:Green WE:Red  ";
    const char *deviceControlText[] = { "Relay Ctrl", "Stepper   ", "DC Motor  ", "Servo     " };
    /* Infinite loop */
    for(;;)
    {
        // 在 LCD 上显示当前的设备控制模式；非继电器模式时追加开关状态
        if(deviceControlMode == RELAY_CONTROL)
        {
            snprintf(row1Text, sizeof(row1Text), "%s", deviceControlText[deviceControlMode]);
        }
        else
        {
            if(motorStartStopState == MOTOR_ON)
            {
                snprintf(row1Text,
                         sizeof(row1Text),
                         "%s %u ON ",
                         deviceControlText[deviceControlMode],
                         (unsigned int)motorMode + 1U);
            }
            else
            {
                snprintf(row1Text,
                         sizeof(row1Text),
                         "%s %u OFF",
                         deviceControlText[deviceControlMode],
                         (unsigned int)motorMode + 1U);
            }
        }
        memset(row1, ' ', 16);
        memcpy(row1, row1Text, strlen(row1Text) > 16 ? 16 : strlen(row1Text));
        row1[16] = '\0';
        LCD_DispString(ROW1, COL1, row1);

        // 在 LCD 上显示当前的交通灯状态，显示在第二行
        switch(trafficLightState)
        {
            case NS_GREEN_WE_RED:
                trafficText = "NS:Green WE:Red  ";
                break;

            case NS_YELLOW_WE_RED:
                trafficText = "NS:Yellow WE:Red ";
                break;

            case NS_RED_WE_GREEN:
                trafficText = "NS:Red WE:Green  ";
                break;

            case NS_RED_WE_YELLOW:
                trafficText = "NS:Red WE:Yellow ";
                break;
        }

        memcpy(row2, trafficText, 16);
        row2[16] = '\0';
        LCD_DispString(ROW2, COL1, row2);

        // 从消息队列接收 DIP 开关状态，显示在第三行，每次显示两位
        uint8_t dipState;
        osMessageQueueGet(DIP2LCDQueueHandle, &dipState, 0, 0);
        memcpy(row3, "DIP:    ", 8);
        for(int i = 0; i < 4; i++)
        {
            // 每次提取两位：先高位后低位
            uint8_t twoBits = (dipState >> (6 - 2 * i)) & 0x03;
            row3[8 + 2 * i] = (char)('0' + ((twoBits >> 1) & 0x01));
            row3[8 + 2 * i + 1] = (char)('0' + (twoBits & 0x01));
        }
        row3[16] = '\0';
        LCD_DispString(ROW3, COL1, row3);

        // 第四行：显示当前直流电机占空比
        {
            uint8_t duty = DCMotor_GetDuty();
            snprintf(row4Text, sizeof(row4Text), "DC Duty: %3u %%", (unsigned int)duty);
        }
        memset(row4, ' ', 16);
        memcpy(row4, row4Text, strlen(row4Text) > 16 ? 16 : strlen(row4Text));
        row4[16] = '\0';
        LCD_DispString(ROW4, COL1, row4);

        osDelay(100);
    }
    /* USER CODE END StartDisplayTask */
}

void
StartSensorTask(void *argument)
{
    /* USER CODE BEGIN StartSensorTask */
    // 初始化传感器
    DHT11_Init();   // 初始化 DHT11 温湿度传感器
    DS18B20_Init(); // 初始化 DS18B20 温度传感器

    /* Infinite loop */
    for(;;)
    {
        // 读取 DHT11 和 DS18B20 传感器数据，并通过 UART 发送队列发送到上位机
        DHT11_Data dht11_data;
        if(DHT11_Read(&dht11_data) == 0)
        {
            UartMsg_t msg;
            int len = snprintf((char *)msg.data,
                               sizeof(msg.data),
                               "DHT11 H:%u.%u T:%u.%u\r\n",
                               (unsigned int)dht11_data.humidity_int,
                               (unsigned int)dht11_data.humidity_dec,
                               (unsigned int)dht11_data.temperature_int,
                               (unsigned int)dht11_data.temperature_dec);

            if(len > 0)
            {
                if(len > UART_TX_MAX_LEN)
                {
                    len = UART_TX_MAX_LEN;
                }
                msg.len = (uint16_t)len;
                (void)osMessageQueuePut(UARTTXQueueHandle, &msg, 0, 0);
            }
        }

        DS18B20_Data ds18b20_data;
        if(DS18B20_Read(&ds18b20_data) == 0)
        {
            UartMsg_t msg;
            int16_t temp_x10 = ds18b20_data.temperature_x10;
            int16_t abs_x10 = (temp_x10 < 0) ? (int16_t)(-temp_x10) : temp_x10;
            int16_t int_part = (int16_t)(abs_x10 / 10);
            int16_t dec_part = (int16_t)(abs_x10 % 10);
            char sign = (temp_x10 < 0) ? '-' : '+';
            int len = snprintf((char *)msg.data,
                               sizeof(msg.data),
                               "DS18B20 T:%c%d.%d\r\n",
                               sign,
                               (int)int_part,
                               (int)dec_part);

            if(len > 0)
            {
                if(len > UART_TX_MAX_LEN)
                {
                    len = UART_TX_MAX_LEN;
                }
                msg.len = (uint16_t)len;
                (void)osMessageQueuePut(UARTTXQueueHandle, &msg, 0, 0);
            }
        }

        osDelay(4000); // 每 4 秒读取一次传感器数据
    }
    /* USER CODE END StartSensorTask */
}

void
StartMotorTask(void *argument)
{
    /* USER CODE BEGIN StartMotorTask */
    Stepper_Init();    // 初始化步进电机
    DCMotor_Init();    // 初始化直流电机
    ServoMotor_Init(); // 初始化舵机

    /* Infinite loop */
    for(;;)
    {
        // KEY0 用来控制步进电机 / 直流电机 / 舵机开关，KEY1 用来控制步进电机 / 直流电机 /
        // 舵机状态切换
        if(deviceControlMode != RELAY_CONTROL)
        {
            if(keyEvent[0] == KEY_EVENT_CLICK)
            {
                keyEvent[0] = KEY_EVENT_NONE; // 清除事件
                motorStartStopState =
                  (motorStartStopState == MOTOR_OFF) ? MOTOR_ON : MOTOR_OFF; // 切换电机开关状态
            }
            if(keyEvent[1] == KEY_EVENT_CLICK)
            {
                keyEvent[1] = KEY_EVENT_NONE; // 清除事件
                motorMode =
                  (motorMode == MOTOR_MODE1) ? MOTOR_MODE2 : MOTOR_MODE1; // 切换电机预设模式
            }
            // KEY2: 直流电机模式下增加占空比
            if(keyEvent[2] == KEY_EVENT_CLICK)
            {
                keyEvent[2] = KEY_EVENT_NONE; // 清除事件
                if(deviceControlMode == DC_MOTOR_CONTROL)
                {
                    DCMotor_AdjustDuty(+10);
                }
            }
        }

        // 根据当前的设备控制模式和电机状态，控制对应设备的运行
        switch(deviceControlMode)
        {
            // 步进电机
            case STEPPER_MOTOR_CONTROL:
                if(motorStartStopState == MOTOR_ON)
                {
                    switch(motorMode)
                    {
                        case MOTOR_MODE1:
                            Stepper_RotateAngle(90.0f, 1000); // 正转 90 度
                            osDelay(200);                     // 运行一段时间后再切换状态
                            break;
                        case MOTOR_MODE2:
                            Stepper_RotateAngle(-90.0f, 1000); // 反转 90 度
                            osDelay(200);                      // 运行一段时间后再切换状态
                            break;
                    }
                }
                else
                {
                    Stepper_Stop(); // 步进电机关闭时停止输出
                }

                DCMotor_Brake();   // 其他模式时直流电机制动
                ServoMotor_Home(); // 其他模式时舵机归零
                break;
            // 直流电机
            case DC_MOTOR_CONTROL:
                if(motorStartStopState == MOTOR_ON)
                {
                    uint8_t duty = DCMotor_GetDuty();
                    switch(motorMode)
                    {
                        case MOTOR_MODE1:
                            DCMotor_Forward(duty);
                            break;

                        case MOTOR_MODE2:
                            DCMotor_Reverse(duty);
                            break;
                    }
                }
                else
                {
                    DCMotor_Brake(); // 直流电机关闭时制动
                }

                Stepper_Stop();    // 其他模式时步进电机停止
                ServoMotor_Home(); // 其他模式时舵机归零
                break;
            // 舵机
            case SERVO_MOTOR_CONTROL:
                if(motorStartStopState == MOTOR_ON)
                {
                    switch(motorMode)
                    {
                        case MOTOR_MODE1:
                            ServoMotor_Mode1();
                            break;
                        case MOTOR_MODE2:
                            ServoMotor_Mode2();
                            break;
                    }
                }
                else
                {
                    ServoMotor_Home(); // 舵机关闭时归零
                }

                Stepper_Stop();  // 其他模式时步进电机停止
                DCMotor_Brake(); // 其他模式时直流电机制动
                break;
            default:
                Stepper_Stop();    // 其他模式时步进电机停止
                DCMotor_Brake();   // 其他模式时直流电机制动
                ServoMotor_Home(); // 其他模式时舵机归零
                break;
        }
        osDelay(10);
    }
    /* USER CODE END StartMotorTask */
}

void
StartInfraredTask(void *argument)
{
    /* USER CODE BEGIN StartInfraredTask */
    /* Infinite loop */
    for(;;)
    {
        // 读取红外接收器状态，并通过串口输出按键值
        if(IR_Is_Data_Ready())
        {
            // 重复码不发送，只发送首次按键和不同按键的切换
            if(!IR_Is_Repeat())
            {
                uint8_t cmd = IR_Get_Command();
                const char *irKey = IR_Get_Key();

                // 每次接收到按键命令时，蜂鸣器响 100 ms
                HAL_GPIO_WritePin(BUZZER_GPIO_Port, BUZZER_Pin, GPIO_PIN_SET);
                osDelay(100);
                HAL_GPIO_WritePin(BUZZER_GPIO_Port, BUZZER_Pin, GPIO_PIN_RESET);

                // ── 红外遥控控制逻辑 ──────────────────────────────
                if(cmd == 0x40) // NEXT: 向后切换设备控制模式
                {
                    switch(deviceControlMode)
                    {
                        case RELAY_CONTROL:
                            deviceControlMode = STEPPER_MOTOR_CONTROL;
                            break;
                        case STEPPER_MOTOR_CONTROL:
                            deviceControlMode = DC_MOTOR_CONTROL;
                            break;
                        case DC_MOTOR_CONTROL:
                            deviceControlMode = SERVO_MOTOR_CONTROL;
                            break;
                        case SERVO_MOTOR_CONTROL:
                            deviceControlMode = RELAY_CONTROL;
                            break;
                    }
                    // 切换设备控制模式时，电机关闭，预设模式重置
                    motorStartStopState = MOTOR_OFF;
                    motorMode = MOTOR_MODE1;
                }
                else if(cmd == 0x44) // PREV: 向前切换设备控制模式
                {
                    switch(deviceControlMode)
                    {
                        case RELAY_CONTROL:
                            deviceControlMode = SERVO_MOTOR_CONTROL;
                            break;
                        case SERVO_MOTOR_CONTROL:
                            deviceControlMode = DC_MOTOR_CONTROL;
                            break;
                        case DC_MOTOR_CONTROL:
                            deviceControlMode = STEPPER_MOTOR_CONTROL;
                            break;
                        case STEPPER_MOTOR_CONTROL:
                            deviceControlMode = RELAY_CONTROL;
                            break;
                    }
                    // 切换设备控制模式时，电机关闭，预设模式重置
                    motorStartStopState = MOTOR_OFF;
                    motorMode = MOTOR_MODE1;
                }
                else if(cmd == 0x45) // CH-: 继电器模式控制 RELAY0；非继电器模式切换预设模式
                {
                    if(deviceControlMode == RELAY_CONTROL)
                    {
                        HAL_GPIO_TogglePin(RELAY0_GPIO_Port, RELAY0_Pin);
                    }
                    else
                    {
                        motorMode = (motorMode == MOTOR_MODE1) ? MOTOR_MODE2 : MOTOR_MODE1;
                    }
                }
                else if(cmd == 0x47) // CH+: 继电器模式控制 RELAY1；非继电器模式切换预设模式
                {
                    if(deviceControlMode == RELAY_CONTROL)
                    {
                        HAL_GPIO_TogglePin(RELAY1_GPIO_Port, RELAY1_Pin);
                    }
                    else
                    {
                        motorMode = (motorMode == MOTOR_MODE1) ? MOTOR_MODE2 : MOTOR_MODE1;
                    }
                }
                else if(cmd == 0x43) // PLAY/PAUSE: 非继电器模式下控制电机开关
                {
                    if(deviceControlMode != RELAY_CONTROL)
                    {
                        motorStartStopState =
                          (motorStartStopState == MOTOR_OFF) ? MOTOR_ON : MOTOR_OFF;
                    }
                }
                else if(cmd == 0x07) // VOL-: 直流电机模式下减少占空比
                {
                    if(deviceControlMode == DC_MOTOR_CONTROL)
                    {
                        DCMotor_AdjustDuty(-10);
                    }
                }
                else if(cmd == 0x15) // VOL+: 直流电机模式下增加占空比
                {
                    if(deviceControlMode == DC_MOTOR_CONTROL)
                    {
                        DCMotor_AdjustDuty(+10);
                    }
                }

                // 通过串口输出按键值
                UartMsg_t msg;
                int len = snprintf((char *)msg.data, sizeof(msg.data), "IR Key: %s\r\n", irKey);
                if(len > 0)
                {
                    if(len > UART_TX_MAX_LEN)
                    {
                        len = UART_TX_MAX_LEN;
                    }
                    msg.len = (uint16_t)len;
                    (void)osMessageQueuePut(UARTTXQueueHandle, &msg, 0, 0);
                }
            }
            // 无论是否发送，都需清除数据就绪标志以接收下一帧
            IR_Clear_Data_Ready();
        }
        osDelay(100);
    }
    /* USER CODE END StartInfraredTask */
}

void
StartDACTask(void *argument)
{
    /* USER CODE BEGIN StartDACTask */
    uint16_t dacValue = 0; // DAC 输出值，范围 0~1023

    /* Infinite loop */
    for(;;)
    {
        // 将 dacValue 转换为 12 位值，输出到 TLC5615
        uint16_t tlcValue = (dacValue & 0x03FF) << 2; // 左移 2 位，适配 TLC5615 的 12 位输入
        // 通过 SPI DMA 发送 tlcValue 到 TLC5615
        HAL_GPIO_WritePin(TLC5615_CS_GPIO_Port, TLC5615_CS_Pin, GPIO_PIN_RESET); // 片选拉低
        HAL_SPI_Transmit_DMA(&hspi3, (uint8_t *)&tlcValue, 1);
        HAL_GPIO_WritePin(TLC5615_CS_GPIO_Port, TLC5615_CS_Pin, GPIO_PIN_SET); // 片选拉高

        // 改变 dacValue 的值，实现呼吸灯效果
        dacValue += 25;
        if(dacValue > 500)
        {
            dacValue = 0;
        }
        osDelay(100);
    }
    /* USER CODE END StartDACTask */
}

void
StartCH451Task(void *argument)
{
    /* USER CODE BEGIN StartCH451Task */
    CH451_Init();
    CH451_ClearDisplay();

    /* Infinite loop */
    for(;;)
    {
        if(CH451_KeyPressed())
        {
            uint8_t keycode = CH451_ReadKeyCode();
            uint8_t row = CH451_GetKeyRow(keycode);
            uint8_t col = CH451_GetKeyCol(keycode);
            uint8_t pressed = CH451_IsKeyPress(keycode);
            CH451_DisplayKeyMatrix(row, col, pressed);
        }
        osDelay(20);
    }
    /* USER CODE END StartCH451Task */
}
